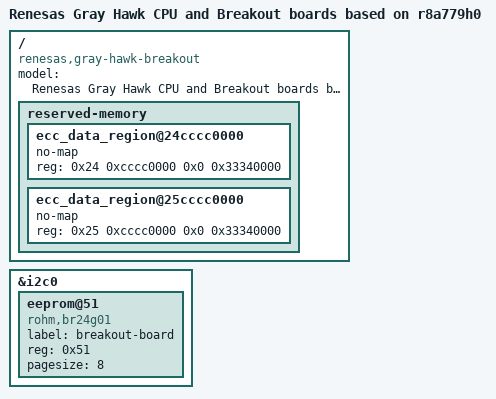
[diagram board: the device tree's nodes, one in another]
// SPDX-License-Identifier: (GPL-2.0-only OR BSD-2-Clause)
/*
 * Device Tree Source for the Gray Hawk CPU and BreakOut boards
 *
 * Copyright (C) 2023 Renesas Electronics Corp.
 */

/dts-v1/;
#include "r8a779h0-gray-hawk-cpu.dtsi"
#include "r8a779h0-gray-hawk-csi-dsi.dtsi"
#include "r8a779h0-gray-hawk-ethernet.dtsi"

/ {
	model = "Renesas Gray Hawk CPU and Breakout boards based on r8a779h0";
	compatible = "renesas,gray-hawk-breakout", "renesas,gray-hawk-cpu", "renesas,r8a779h0";

	reserved-memory {
                #address-cells = <2>;
                #size-cells = <2>;
                ranges;

		ecc_data_region@24cccc0000 {
			no-map;
			reg = <0x24 0xcccc0000 0x0 0x33340000>;
		};

		ecc_data_region@25cccc0000 {
			no-map;
			reg = <0x25 0xcccc0000 0x0 0x33340000>;
		};
	};
};

&i2c0 {
	eeprom@51 {
		compatible = "rohm,br24g01", "atmel,24c01";
		label = "breakout-board";
		reg = <0x51>;
		pagesize = <8>;
	};
};
